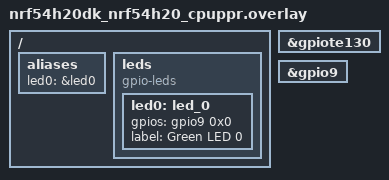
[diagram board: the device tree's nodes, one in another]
/* SPDX-License-Identifier: Apache-2.0 */

#include "nrf54h20dk_nrf54h20_common.dtsi"

/ {
	aliases {
		led0 = &led0;
	};

	leds {
		compatible = "gpio-leds";
		led0: led_0 {
			gpios = < &gpio9 0x0 0x0 >;
			label = "Green LED 0";
		};
	};
};

&gpiote130 {
	status = "okay";
};

&gpio9 {
	status = "okay";
};
